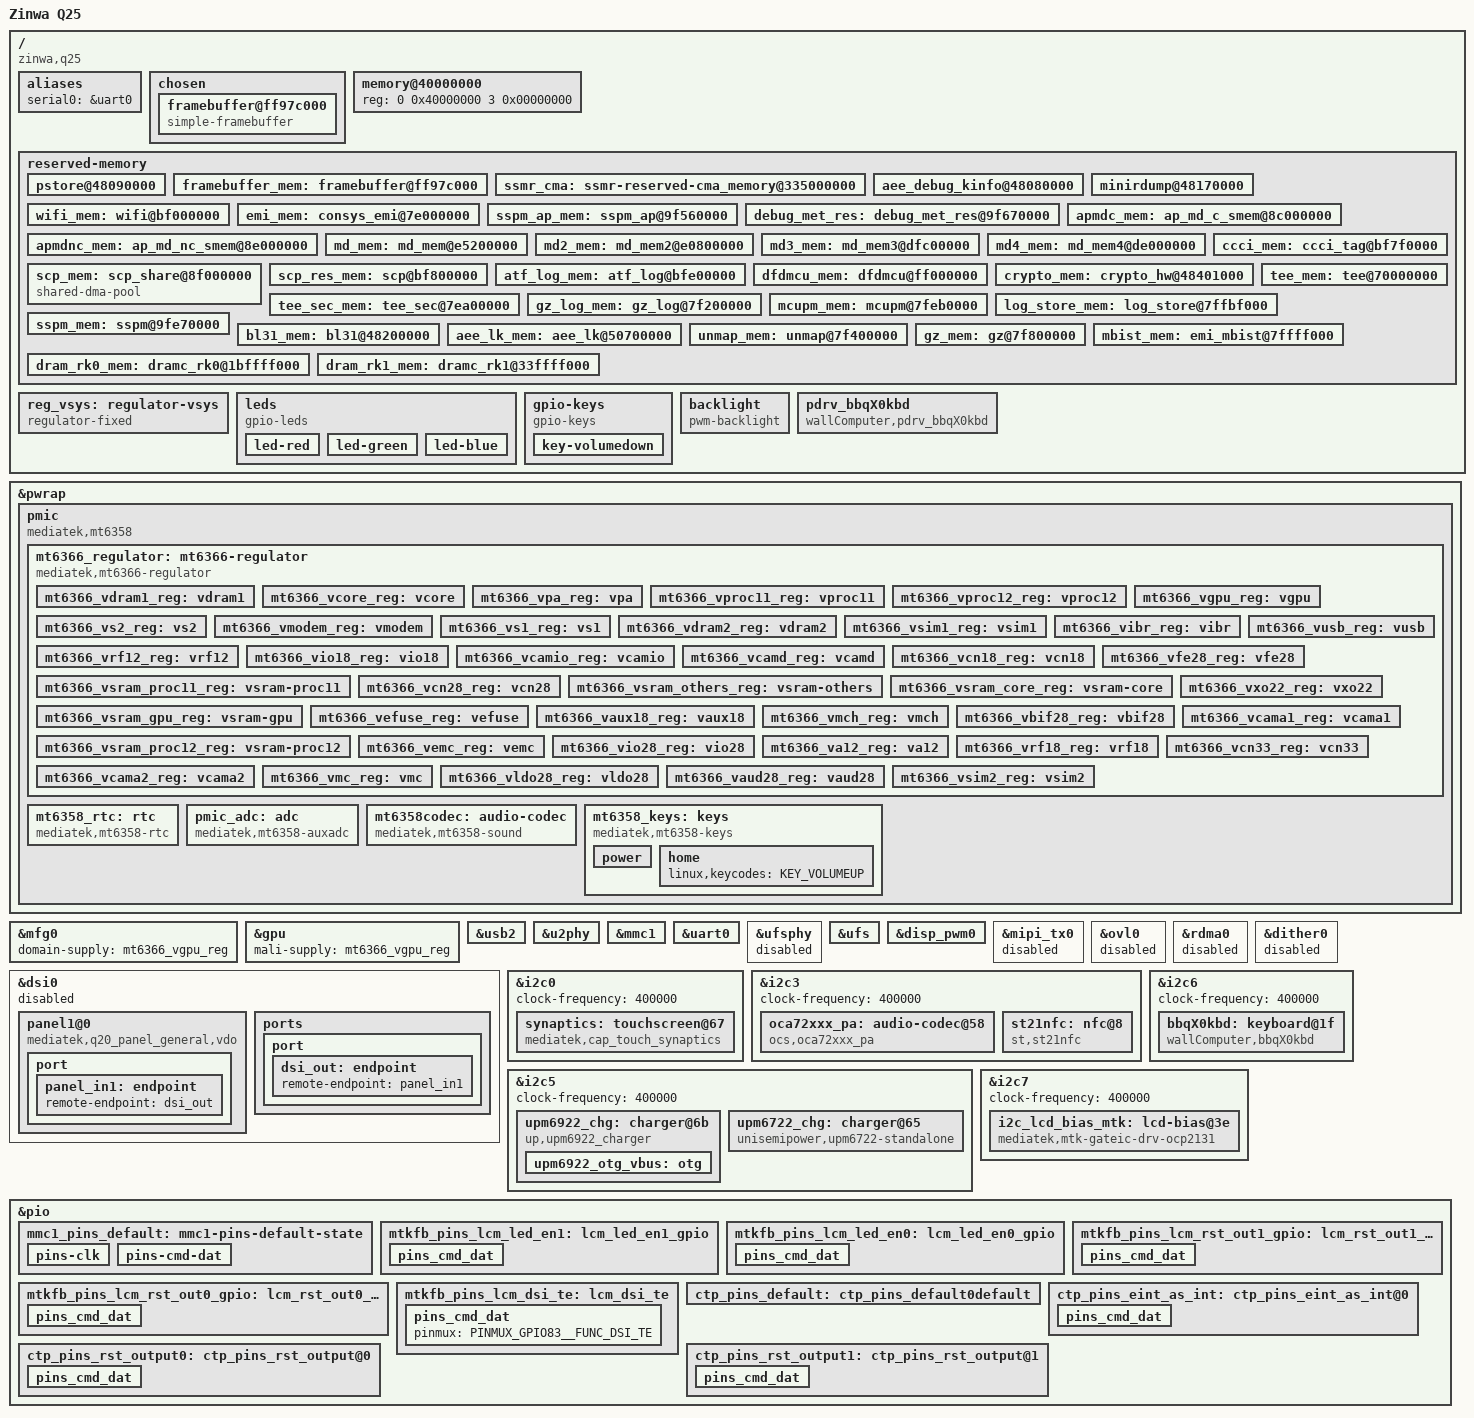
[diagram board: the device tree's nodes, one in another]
// SPDX-License-Identifier: GPL-2.0
/*
 * Device Tree Source for Zinwa Q25 (Xelex Q20 v12 / MediaTek Helio G99 MT6789 / MT8781)
 *
 * Mainline Linux 7.0+ DeviceTree with full Q25 peripheral wiring:
 * - BBQX0 Physical QWERTY Keyboard + Optical Trackpad (&i2c6 @ 0x1f + pdrv_bbqX0kbd)
 * - Synaptics S2716B 720x720 Capacitive Touchscreen (&i2c0 @ 0x67)
 * - Q20 720x720 60Hz MIPI DSI Video Panel (&dsi0) + OCP2131 Bias IC (&i2c7 @ 0x3e)
 * - UPM6922 Primary Charger + OTG VBUS (&i2c5 @ 0x6b) & UPM6722 Charge Pump (&i2c5 @ 0x65)
 * - OCA72xxx Smart Audio PA (&i2c3 @ 0x58)
 * - ST21NFC Controller (&i2c3 @ 0x08)
 * - RGB Status LEDs (GPIO 46/48/49) & Hardware Keys (PMIC Power/VolUp + GPIO 43 VolDown)
 * - Arm Mali-G57 MC2 GPU (Open-Source Panfrost)
 */

/dts-v1/;

#include <dt-bindings/input/input.h>
#include <dt-bindings/gpio/gpio.h>
#include <dt-bindings/iio/adc/mediatek,mt6358-auxadc.h>
#include <dt-bindings/regulator/mediatek,mt6397-regulator.h>
#include <dt-bindings/pinctrl/mediatek,mt6789-pinfunc.h>
#include "mt6789.dtsi"

/ {
	model = "Zinwa Q25";
	chassis-type = "handset";
	compatible = "zinwa,q25", "mediatek,mt8781", "mediatek,mt6789";

	#address-cells = <2>;
	#size-cells = <2>;

	aliases {
		serial0 = &uart0;
	};

	chosen: chosen {
		#address-cells = <2>;
		#size-cells = <2>;
		ranges;

		stdout-path = "serial0:921600n1";
		bootargs = "console=tty0 loglevel=8 earlycon panic=5 clk_ignore_unused pd_ignore_unused initcall_debug=1 ramoops.mem_address=0x48090000 ramoops.mem_size=0xcf000 ramoops.record_size=0x1000 ramoops.console_size=0x40000 ramoops.ftrace_size=0 ramoops.pmsg_size=0 arm64.nomte";
		linux,initrd-start = <0 0x66f00000>;
		linux,initrd-end = <0 0x69202911>;

		framebuffer@ff97c000 {
			compatible = "simple-framebuffer";
			memory-region = <&framebuffer_mem>;
			reg = <0 0xff97c000 0 ((720 + 16) * 720 * 4)>;
			width = <720>;
			height = <720>;
			stride = <((720 + 16) * 4)>;
			format = "a8r8g8b8";
		};
	};

	memory@40000000 {
		device_type = "memory";
		reg = <0 0x40000000 3 0x00000000>;
	};

	reserved-memory {
		#address-cells = <2>;
		#size-cells = <2>;
		ranges;

		pstore@48090000 {
			reg = <0 0x48090000 0 0xe0000>;
			no-map;
		};

		framebuffer_mem: framebuffer@ff97c000 {
			reg = <0 0xff97c000 0 0x683000>;
			no-map;
		};

		ssmr_cma: ssmr-reserved-cma_memory@335000000 {
			reg = <0x3 0x35000000 0 0x0a000000>;
			no-map;
		};

		aee_debug_kinfo@48080000 {
			reg = <0 0x48080000 0 0x10000>;
			no-map;
		};

		minirdump@48170000 {
			reg = <0 0x48170000 0 0x10000>;
			no-map;
		};

		wifi_mem: wifi@bf000000 {
			reg = <0 0xbf000000 0 0x600000>;
			no-map;
		};

		emi_mem: consys_emi@7e000000 {
			reg = <0 0x7e000000 0 0x500000>;
			no-map;
		};

		sspm_ap_mem: sspm_ap@9f560000 {
			reg = <0 0x9f560000 0 0x110000>;
			no-map;
		};

		debug_met_res: debug_met_res@9f670000 {
			reg = <0 0x9f670000 0 0x800000>;
			no-map;
		};

		apmdc_mem: ap_md_c_smem@8c000000 {
			reg = <0 0x8c000000 0 0x16a0000>;
			no-map;
		};

		apmdnc_mem: ap_md_nc_smem@8e000000 {
			reg = <0 0x8e000000 0 0xe10000>;
			no-map;
		};

		md_mem: md_mem@e5200000 {
			reg = <0 0xe5200000 0 0xe00000>;
			no-map;
		};

		md2_mem: md_mem2@e0800000 {
			reg = <0 0xe0800000 0 0x2c50000>;
			no-map;
		};

		md3_mem: md_mem3@dfc00000 {
			reg = <0 0xdfc00000 0 0x430000>;
			no-map;
		};

		md4_mem: md_mem4@de000000 {
			reg = <0 0xde000000 0 0x13f0000>;
			no-map;
		};

		ccci_mem: ccci_tag@bf7f0000 {
			reg = <0 0xbf7f0000 0 0x10000>;
			no-map;
		};

		scp_mem: scp_share@8f000000 {
			reg = <0 0x8f000000 0 0x7a0000>;
			compatible = "shared-dma-pool";
			no-map;
		};

		scp_res_mem: scp@bf800000 {
			reg = <0 0xbf800000 0 0x600000>;
			no-map;
		};

		atf_log_mem: atf_log@bfe00000 {
			reg = <0 0xbfe00000 0 0x200000>;
			no-map;
		};

		dfdmcu_mem: dfdmcu@ff000000 {
			reg = <0 0xff000000 0 0x100000>;
			no-map;
		};

		crypto_mem: crypto_hw@48401000 {
			reg = <0 0x48401000 0 0x1000>;
			no-map;
		};

		tee_mem: tee@70000000 {
			reg = <0 0x70000000 0 0x4600000>;
			no-map;
		};

		tee_sec_mem: tee_sec@7ea00000 {
			reg = <0 0x7ea00000 0 0x800000>;
			no-map;
		};

		gz_log_mem: gz_log@7f200000 {
			reg = <0 0x7f200000 0 0x41000>;
			no-map;
		};

		mcupm_mem: mcupm@7feb0000 {
			reg = <0 0x7feb0000 0 0x100000>;
			no-map;
		};

		log_store_mem: log_store@7ffbf000 {
			reg = <0 0x7ffbf000 0 0x40000>;
			no-map;
		};

		sspm_mem: sspm@9fe70000 {
			reg = <0 0x9fe70000 0 0x180000>;
			no-map;
		};

		bl31_mem: bl31@48200000 {
			reg = <0 0x48200000 0 0x200000>;
			no-map;
		};

		aee_lk_mem: aee_lk@50700000 {
			reg = <0 0x50700000 0 0x800000>;
			no-map;
		};

		unmap_mem: unmap@7f400000 {
			reg = <0 0x7f400000 0 0x400000>;
			no-map;
		};

		gz_mem: gz@7f800000 {
			reg = <0 0x7f800000 0 0x600000>;
			no-map;
		};

		mbist_mem: emi_mbist@7ffff000 {
			reg = <0 0x7ffff000 0 0x1000>;
			no-map;
		};

		dram_rk0_mem: dramc_rk0@1bffff000 {
			reg = <0x1 0xbffff000 0 0x1000>;
			no-map;
		};

		dram_rk1_mem: dramc_rk1@33ffff000 {
			reg = <0x3 0x3ffff000 0 0x1000>;
			no-map;
		};
	};

	reg_vsys: regulator-vsys {
		compatible = "regulator-fixed";
		regulator-name = "vsys";
		regulator-always-on;
		regulator-boot-on;
	};

	/* Zinwa Q25 RGB Notification LEDs */
	leds {
		compatible = "gpio-leds";

		led-red {
			label = "red";
			gpios = <&pio 46 GPIO_ACTIVE_HIGH>;
			default-state = "keep";
		};

		led-green {
			label = "green";
			gpios = <&pio 48 GPIO_ACTIVE_HIGH>;
			default-state = "keep";
		};

		led-blue {
			label = "blue";
			gpios = <&pio 49 GPIO_ACTIVE_HIGH>;
			default-state = "off";
		};
	};

	/* Volume Down GPIO key (KPD_KCOL0 on GPIO 43) */
	gpio-keys {
		compatible = "gpio-keys";

		key-volumedown {
			label = "Volume Down";
			gpios = <&pio 43 GPIO_ACTIVE_LOW>;
			linux,code = <KEY_VOLUMEDOWN>;
			debounce-interval = <15>;
			wakeup-source;
		};
	};

	/* Display PWM Backlight */
	backlight: backlight {
		compatible = "pwm-backlight";
		pwms = <&disp_pwm0 0 500000>;
		brightness-levels = <0 1023>;
		num-interpolated-steps = <1023>;
		default-brightness-level = <400>;
	};

	/* Zinwa Q25 Keyboard & Optical Trackpad Power Sequencing / Firmware Control */
	pdrv_bbqX0kbd: pdrv_bbqX0kbd {
		compatible = "wallComputer,pdrv_bbqX0kbd";
		irq-gpio = <&pio 12 GPIO_ACTIVE_HIGH>;
		int-gpios = <&pio 12 GPIO_ACTIVE_HIGH>;
		power-vdd-gpios = <&pio 159 GPIO_ACTIVE_HIGH>;
		power-1v8-gpios = <&pio 157 GPIO_ACTIVE_HIGH>;
		power-2v8-gpios = <&pio 158 GPIO_ACTIVE_HIGH>;
		firmware-download-gpios = <&pio 47 GPIO_ACTIVE_HIGH>;
	};
};

&pwrap {
	status = "okay";

	pmic: pmic {
		compatible = "mediatek,mt6358";
		interrupt-controller;
		interrupts-extended = <&pio 137 IRQ_TYPE_LEVEL_HIGH>;
		#interrupt-cells = <2>;

		mt6366_regulator: mt6366-regulator {
			compatible = "mediatek,mt6366-regulator", "mediatek,mt6358-regulator";

			vsys-ldo1-supply = <&reg_vsys>;
			vsys-ldo2-supply = <&reg_vsys>;
			vsys-ldo3-supply = <&reg_vsys>;
			vsys-vs1-supply = <&reg_vsys>;
			vsys-vs2-supply = <&reg_vsys>;
			vsys-vdram1-supply = <&reg_vsys>;
			vsys-vcore-supply = <&reg_vsys>;
			vsys-vpa-supply = <&reg_vsys>;
			vsys-vproc11-supply = <&reg_vsys>;
			vsys-vproc12-supply = <&reg_vsys>;
			vsys-vgpu-supply = <&reg_vsys>;
			vsys-vmodem-supply = <&reg_vsys>;
			vs1-ldo1-supply = <&mt6366_vs1_reg>;
			vs2-ldo1-supply = <&mt6366_vdram1_reg>;
			vs2-ldo2-supply = <&mt6366_vs2_reg>;
			vs2-ldo3-supply = <&mt6366_vs2_reg>;

			mt6366_vdram1_reg: vdram1 {
				regulator-name = "vdram1";
				regulator-min-microvolt = <500000>;
				regulator-max-microvolt = <2087500>;
				regulator-ramp-delay = <12500>;
				regulator-enable-ramp-delay = <0>;
				regulator-always-on;
				regulator-allowed-modes = <MT6397_BUCK_MODE_AUTO
				                           MT6397_BUCK_MODE_FORCE_PWM>;
			};

			mt6366_vcore_reg: vcore {
				regulator-name = "vcore";
				regulator-min-microvolt = <500000>;
				regulator-max-microvolt = <1293750>;
				regulator-ramp-delay = <6250>;
				regulator-enable-ramp-delay = <200>;
				regulator-always-on;
				regulator-allowed-modes = <MT6397_BUCK_MODE_AUTO
				                           MT6397_BUCK_MODE_FORCE_PWM>;
			};

			mt6366_vpa_reg: vpa {
				regulator-name = "vpa";
				regulator-min-microvolt = <500000>;
				regulator-max-microvolt = <3650000>;
				regulator-ramp-delay = <50000>;
				regulator-enable-ramp-delay = <250>;
				regulator-allowed-modes = <MT6397_BUCK_MODE_AUTO
				                           MT6397_BUCK_MODE_FORCE_PWM>;
			};

			mt6366_vproc11_reg: vproc11 {
				regulator-name = "vproc11";
				regulator-min-microvolt = <500000>;
				regulator-max-microvolt = <1293750>;
				regulator-ramp-delay = <6250>;
				regulator-enable-ramp-delay = <200>;
				regulator-always-on;
				regulator-allowed-modes = <MT6397_BUCK_MODE_AUTO
				                           MT6397_BUCK_MODE_FORCE_PWM>;
			};

			mt6366_vproc12_reg: vproc12 {
				regulator-name = "vproc12";
				regulator-min-microvolt = <500000>;
				regulator-max-microvolt = <1293750>;
				regulator-ramp-delay = <6250>;
				regulator-enable-ramp-delay = <200>;
				regulator-always-on;
				regulator-allowed-modes = <MT6397_BUCK_MODE_AUTO
				                           MT6397_BUCK_MODE_FORCE_PWM>;
			};

			mt6366_vgpu_reg: vgpu {
				regulator-name = "vgpu";
				regulator-min-microvolt = <675000>;
				regulator-max-microvolt = <1293750>;
				regulator-ramp-delay = <6250>;
				regulator-enable-ramp-delay = <200>;
				regulator-always-on;
				regulator-boot-on;
				regulator-allowed-modes = <MT6397_BUCK_MODE_AUTO
				                           MT6397_BUCK_MODE_FORCE_PWM>;

				regulator-coupled-with = <&mt6366_vsram_gpu_reg>;
				regulator-coupled-max-spread = <100000>;
			};

			mt6366_vs2_reg: vs2 {
				regulator-name = "vs2";
				regulator-min-microvolt = <500000>;
				regulator-max-microvolt = <2087500>;
				regulator-ramp-delay = <12500>;
				regulator-enable-ramp-delay = <0>;
				regulator-always-on;
			};

			mt6366_vmodem_reg: vmodem {
				regulator-name = "vmodem";
				regulator-min-microvolt = <500000>;
				regulator-max-microvolt = <1293750>;
				regulator-ramp-delay = <6250>;
				regulator-enable-ramp-delay = <900>;
				regulator-always-on;
				regulator-allowed-modes = <MT6397_BUCK_MODE_AUTO
				                           MT6397_BUCK_MODE_FORCE_PWM>;
			};

			mt6366_vs1_reg: vs1 {
				regulator-name = "vs1";
				regulator-min-microvolt = <1000000>;
				regulator-max-microvolt = <2587500>;
				regulator-ramp-delay = <12500>;
				regulator-enable-ramp-delay = <0>;
				regulator-always-on;
			};

			/* LPDDR4X, always on */
			mt6366_vdram2_reg: vdram2 {
				regulator-name = "vdram2";
				regulator-min-microvolt = <600000>;
				regulator-max-microvolt = <1800000>;
				regulator-enable-ramp-delay = <3300>;
				regulator-always-on;
			};

			mt6366_vsim1_reg: vsim1 {
				regulator-name = "vsim1";
				regulator-min-microvolt = <1700000>;
				regulator-max-microvolt = <3100000>;
				regulator-enable-ramp-delay = <540>;
			};

			mt6366_vibr_reg: vibr {
				regulator-name = "vibr";
				regulator-min-microvolt = <1200000>;
				regulator-max-microvolt = <3300000>;
				regulator-enable-ramp-delay = <60>;
			};

			mt6366_vrf12_reg: vrf12 {
				regulator-name = "vrf12";
				regulator-min-microvolt = <1200000>;
				regulator-max-microvolt = <1200000>;
				regulator-enable-ramp-delay = <120>;
				regulator-always-on;
				regulator-boot-on;
			};

			mt6366_vio18_reg: vio18 {
				regulator-name = "vio18";
				regulator-min-microvolt = <1800000>;
				regulator-max-microvolt = <1800000>;
				regulator-enable-ramp-delay = <2700>;
				regulator-always-on;
				regulator-boot-on;
			};

			mt6366_vusb_reg: vusb {
				regulator-name = "vusb";
				regulator-min-microvolt = <3000000>;
				regulator-max-microvolt = <3100000>;
				regulator-enable-ramp-delay = <270>;
				regulator-always-on;
			};

			mt6366_vcamio_reg: vcamio {
				regulator-name = "vcamio";
				regulator-min-microvolt = <1800000>;
				regulator-max-microvolt = <1800000>;
				regulator-enable-ramp-delay = <325>;
			};

			mt6366_vcamd_reg: vcamd {
				regulator-name = "vcamd";
				regulator-min-microvolt = <900000>;
				regulator-max-microvolt = <1800000>;
				regulator-enable-ramp-delay = <325>;
			};

			mt6366_vcn18_reg: vcn18 {
				regulator-name = "vcn18";
				regulator-min-microvolt = <1800000>;
				regulator-max-microvolt = <1800000>;
				regulator-enable-ramp-delay = <270>;
				regulator-boot-on;
				regulator-always-on;
			};

			mt6366_vfe28_reg: vfe28 {
				regulator-name = "vfe28";
				regulator-min-microvolt = <2800000>;
				regulator-max-microvolt = <2800000>;
				regulator-enable-ramp-delay = <270>;
				regulator-boot-on;
				regulator-always-on;
			};

			mt6366_vsram_proc11_reg: vsram-proc11 {
				regulator-name = "vsram_proc11";
				regulator-min-microvolt = <500000>;
				regulator-max-microvolt = <1293750>;
				regulator-ramp-delay = <6250>;
				regulator-enable-ramp-delay = <240>;
				regulator-always-on;
			};

			mt6366_vcn28_reg: vcn28 {
				regulator-name = "vcn28";
				regulator-min-microvolt = <2800000>;
				regulator-max-microvolt = <2800000>;
				regulator-enable-ramp-delay = <270>;
				regulator-boot-on;
				regulator-always-on;
			};

			mt6366_vsram_others_reg: vsram-others {
				regulator-name = "vsram_others";
				regulator-min-microvolt = <500000>;
				regulator-max-microvolt = <1293750>;
				regulator-ramp-delay = <6250>;
				regulator-enable-ramp-delay = <240>;
				regulator-always-on;
			};

			mt6366_vsram_core_reg: vsram-core {
				regulator-name = "vsram_core";
				regulator-min-microvolt = <500000>;
				regulator-max-microvolt = <1293750>;
				regulator-enable-ramp-delay = <240>;
				regulator-always-on;
			};

			mt6366_vsram_gpu_reg: vsram-gpu {
				regulator-name = "vsram_gpu";
				regulator-min-microvolt = <775000>;
				regulator-max-microvolt = <1293750>;
				regulator-ramp-delay = <6250>;
				regulator-enable-ramp-delay = <240>;
				regulator-always-on;
				regulator-boot-on;

				regulator-coupled-with = <&mt6366_vgpu_reg>;
				regulator-coupled-max-spread = <100000>;
			};

			mt6366_vxo22_reg: vxo22 {
				regulator-name = "vxo22";
				regulator-min-microvolt = <2200000>;
				regulator-max-microvolt = <2200000>;
				regulator-enable-ramp-delay = <120>;
				regulator-always-on;
				regulator-boot-on;
			};

			mt6366_vefuse_reg: vefuse {
				regulator-name = "vefuse";
				regulator-min-microvolt = <1700000>;
				regulator-max-microvolt = <1900000>;
				regulator-enable-ramp-delay = <270>;
			};

			mt6366_vaux18_reg: vaux18 {
				regulator-name = "vaux18";
				regulator-min-microvolt = <1800000>;
				regulator-max-microvolt = <1800000>;
				regulator-enable-ramp-delay = <270>;
				regulator-always-on;
				regulator-boot-on;
			};

			mt6366_vmch_reg: vmch {
				regulator-name = "vmch";
				regulator-min-microvolt = <2900000>;
				regulator-max-microvolt = <3300000>;
				regulator-enable-ramp-delay = <60>;
				regulator-always-on;
			};

			mt6366_vbif28_reg: vbif28 {
				regulator-name = "vbif28";
				regulator-min-microvolt = <2800000>;
				regulator-max-microvolt = <2800000>;
				regulator-enable-ramp-delay = <270>;
			};

			mt6366_vsram_proc12_reg: vsram-proc12 {
				regulator-name = "vsram_proc12";
				regulator-min-microvolt = <500000>;
				regulator-max-microvolt = <1293750>;
				regulator-ramp-delay = <6250>;
				regulator-enable-ramp-delay = <240>;
				regulator-always-on;
			};

			mt6366_vcama1_reg: vcama1 {
				regulator-name = "vcama1";
				regulator-min-microvolt = <1800000>;
				regulator-max-microvolt = <3000000>;
				regulator-enable-ramp-delay = <325>;
				regulator-boot-on;
				regulator-always-on;
			};

			mt6366_vemc_reg: vemc {
				regulator-name = "vemc";
				regulator-min-microvolt = <2900000>;
				regulator-max-microvolt = <3300000>;
				regulator-enable-ramp-delay = <60>;
				regulator-boot-on;
			};

			mt6366_vio28_reg: vio28 {
				regulator-name = "vio28";
				regulator-min-microvolt = <2800000>;
				regulator-max-microvolt = <2800000>;
				regulator-enable-ramp-delay = <270>;
				regulator-boot-on;
				regulator-always-on;
			};

			mt6366_va12_reg: va12 {
				regulator-name = "va12";
				regulator-min-microvolt = <1200000>;
				regulator-max-microvolt = <1200000>;
				regulator-enable-ramp-delay = <270>;
				regulator-always-on;
			};

			mt6366_vrf18_reg: vrf18 {
				regulator-name = "vrf18";
				regulator-min-microvolt = <1800000>;
				regulator-max-microvolt = <1800000>;
				regulator-enable-ramp-delay = <120>;
			};

			mt6366_vcn33_reg: vcn33 {
				regulator-name = "vcn33";
				regulator-min-microvolt = <3300000>;
				regulator-max-microvolt = <3500000>;
				regulator-enable-ramp-delay = <270>;
			};

			mt6366_vcama2_reg: vcama2 {
				regulator-name = "vcama2";
				regulator-min-microvolt = <1800000>;
				regulator-max-microvolt = <3000000>;
				regulator-enable-ramp-delay = <325>;
				regulator-boot-on;
				regulator-always-on;
			};

			mt6366_vmc_reg: vmc {
				regulator-name = "vmc";
				regulator-min-microvolt = <2900000>;
				regulator-max-microvolt = <3300000>;
				regulator-enable-ramp-delay = <60>;
				regulator-boot-on;
				regulator-always-on;
			};

			mt6366_vldo28_reg: vldo28 {
				regulator-name = "vldo28";
				regulator-min-microvolt = <2800000>;
				regulator-max-microvolt = <2800000>;
				regulator-enable-ramp-delay = <270>;
				regulator-boot-on;
				regulator-always-on;
			};

			mt6366_vaud28_reg: vaud28 {
				regulator-name = "vaud28";
				regulator-min-microvolt = <2800000>;
				regulator-max-microvolt = <2800000>;
				regulator-enable-ramp-delay = <270>;
				regulator-boot-on;
				regulator-always-on;
			};

			mt6366_vsim2_reg: vsim2 {
				regulator-name = "vsim2";
				regulator-min-microvolt = <1700000>;
				regulator-max-microvolt = <3100000>;
				regulator-enable-ramp-delay = <540>;
			};
		};

		mt6358_rtc: rtc {
			compatible = "mediatek,mt6358-rtc";
		};

		pmic_adc: adc {
			compatible = "mediatek,mt6358-auxadc";
			#io-channel-cells = <1>;
		};

		mt6358codec: audio-codec {
			compatible = "mediatek,mt6358-sound";
			Avdd-supply = <&mt6366_vaud28_reg>;
			mediatek,dmic-mode = <0>;
		};

		mt6358_keys: keys {
			compatible = "mediatek,mt6358-keys";

			power-off-time-sec = <10>;
			mediatek,long-press-mode = <1>;

			power {
				linux,keycodes = <KEY_POWER>;
				wakeup-source;
			};

			home {
				linux,keycodes = <KEY_VOLUMEUP>;
			};
		};
	};
};

&mfg0 {
	domain-supply = <&mt6366_vgpu_reg>;
};

/* Open-Source Panfrost GPU (Arm Mali-G57 MC2) */
&gpu {
	/delete-property/ operating-points-v2;
	mali-supply = <&mt6366_vgpu_reg>;
	status = "okay";
};

&usb2 {
	status = "okay";
	dr_mode = "peripheral";
	maximum-speed = "high-speed";
};

&u2phy {
	status = "okay";
};

&mmc1 {
	status = "okay";

	pinctrl-names = "default", "state_uhs";
	pinctrl-0 = <&mmc1_pins_default>;
	pinctrl-1 = <&mmc1_pins_default>;

	bus-width = <4>;
	max-frequency = <200000000>;

	cap-sd-highspeed;
	sd-uhs-sdr12;
	sd-uhs-sdr25;
	sd-uhs-sdr50;
	sd-uhs-sdr104;
	sd-uhs-ddr50;

	cd-debounce-delay-ms = <0>;
	cd-gpios = <&pio 7 GPIO_ACTIVE_HIGH>;

	vmmc-supply = <&mt6366_vmch_reg>;
	vqmmc-supply = <&mt6366_vmc_reg>;
};

&uart0 {
	status = "okay";
};

&ufsphy {
	status = "disabled";
};

&ufs {
	status = "okay";
	/delete-property/ phys;
	vcc-supply = <&mt6366_vemc_reg>;
	clocks = <&infracfg_ao CLK_IFRAO_UFS>,
	         <&infracfg_ao CLK_IFRAO_UFS_SAP_BCLK>,
	         <&infracfg_ao CLK_IFRAO_UNIPRO_TICK>,
	         <&infracfg_ao CLK_IFRAO_UNIPRO_SYSCLK>,
	         <&infracfg_ao CLK_IFRAO_UFS_AES>,
	         <&topckgen CLK_TOP_AES_UFSFDE>,
	         <&topckgen CLK_TOP_UFS>,
	         <&topckgen CLK_TOP_UFS_SEL>;
	clock-names = "ufs", "ufs_mp", "unipro_tick", "unipro_sys",
	              "ufs_aes", "ufsfde_ck", "ufs_ck", "ufs_sel";
	freq-table-hz = <0 0>, <0 0>, <0 0>, <0 0>,
	                <0 0>, <0 0>, <0 0>, <0 0>;
};

&disp_pwm0 {
	status = "okay";
};

/* Keep mtk-drm display pipeline disabled while using simple-framebuffer */
&mipi_tx0 {
	status = "disabled";
};

&ovl0 {
	status = "disabled";
};

&rdma0 {
	status = "disabled";
};

&dither0 {
	status = "disabled";
};

/* Q20 720x720 60Hz MIPI DSI Video Panel */
&dsi0 {
	status = "disabled";
	#address-cells = <1>;
	#size-cells = <0>;

	panel1@0 {
		compatible = "mediatek,q20_panel_general,vdo";
		reg = <0>;
		reset-gpios = <&pio 85 GPIO_ACTIVE_HIGH>;
		avdd-gpios = <&pio 156 GPIO_ACTIVE_HIGH>;
		backlight = <&backlight>;
		board_name = "q20_v12";

		port {
			panel_in1: endpoint {
				remote-endpoint = <&dsi_out>;
			};
		};
	};

	ports {
		port {
			dsi_out: endpoint {
				remote-endpoint = <&panel_in1>;
			};
		};
	};
};

/* I2C0: Synaptics S2716B 720x720 Capacitive Touchscreen */
&i2c0 {
	clock-frequency = <400000>;
	status = "okay";

	synaptics: touchscreen@67 {
		compatible = "mediatek,cap_touch_synaptics", "synaptics,dsx-i2c";
		reg = <0x67>;
		boot_mode = <&chosen>;
		synaptics,irq-gpio = <&pio 9 GPIO_ACTIVE_HIGH>;
		synaptics,irq-on-state = <0>;
		synaptics,reset-gpio = <&pio 152 GPIO_ACTIVE_HIGH>;
		synaptics,reset-on-state = <0>;
		synaptics,reset-active-ms = <20>;
		synaptics,reset-delay-ms = <200>;
		synaptics,power-gpio = <&pio 27 GPIO_ACTIVE_HIGH>;
		synaptics,power-on-state = <1>;
		synaptics,power-delay-ms = <200>;
		synaptics,input-device-name = "s2716b_ts";
	};
};

/* I2C3: OCA72xxx Smart Audio PA + ST21NFC Controller */
&i2c3 {
	clock-frequency = <400000>;
	status = "okay";

	oca72xxx_pa: audio-codec@58 {
		compatible = "ocs,oca72xxx_pa", "mediatek,k9_pa";
		reg = <0x58>;
		dev_index = <0>;
		status = "okay";
	};

	st21nfc: nfc@8 {
		compatible = "st,st21nfc";
		reg = <0x08>;
		interrupt-parent = <&pio>;
		interrupts = <1 IRQ_TYPE_LEVEL_LOW>;
		reset-gpios = <&pio 150 GPIO_ACTIVE_HIGH>;
		irq-gpios = <&pio 1 GPIO_ACTIVE_HIGH>;
		clkreq-gpios = <&pio 68 GPIO_ACTIVE_HIGH>;
		status = "okay";
	};
};

/* I2C5: UPM6922 Primary Charger + OTG VBUS & UPM6722 Standalone Charge Pump */
&i2c5 {
	clock-frequency = <400000>;
	status = "okay";

	upm6922_chg: charger@6b {
		compatible = "up,upm6922_charger";
		reg = <0x6b>;
		status = "okay";
		up,intr_gpio = <&pio 37 GPIO_ACTIVE_HIGH>;

		up,upm6922,ichg = <3000>;
		up,upm6922,iprechg = <180>;
		up,upm6922,iterm = <200>;
		up,upm6922,vreg = <4440>;
		up,upm6922,vindpm = <4600>;
		up,upm6922,boostv = <5000>;
		up,upm6922,boosti = <1200>;
		up,upm6922,vac-ovp = <14000>;

		boot_mode = <&chosen>;
		phys = <&u2port0 PHY_TYPE_USB2>;
		phy-names = "usb2-phy";
		io-channels = <&pmic_adc MT6358_AUXADC_VCDT>,
		              <&pmic_adc MT6358_AUXADC_BATADC>;
		io-channel-names = "vbus", "vbat";

		upm6922_otg_vbus: otg {
			regulator-compatible = "upm6922,otg-vbus";
			regulator-name = "usb-otg-vbus";
		};
	};

	upm6722_chg: charger@65 {
		compatible = "unisemipower,upm6722-standalone";
		reg = <0x65>;
		status = "okay";
		upm6722,irq-gpio = <&pio 10 GPIO_ACTIVE_HIGH>;

		upm6722,bat-ocp-disable;
		upm6722,tsbus-flt-disable;
		upm6722,tsbat-flt-disable;
		upm6722,wdt-disable;
		upm6722,vbus-errhi-disable;
		upm6722,bat-ocp-alm-disable;

		upm6722,bat-ovp-threshold = <4525>;
		upm6722,bat-ocp-threshold = <8200>;
		upm6722,bus-ovp-threshold = <12000>;
		upm6722,bus-ocp-threshold = <5100>;
		upm6722,bus-ucp-threshold = <250>;
		upm6722,bus-rcp-threshold = <300>;
		upm6722,vac1-ovp-threshold = <18000>;
		upm6722,vac2-ovp-threshold = <18000>;
		upm6722,vout-ovp-threshold = <5000>;
		upm6722,tdie-flt-threshold = <140>;
		upm6722,tsbus-flt-threshold = <4102>;
		upm6722,tsbat-flt-threshold = <4102>;

		upm6722,bat-ovp-alm-threshold = <4510>;
		upm6722,bat-ocp-alm-threshold = <8000>;
		upm6722,bat-ucp-alm-threshold = <0>;
		upm6722,bus-ovp-alm-threshold = <11800>;
		upm6722,bus-ocp-alm-threshold = <5000>;
		upm6722,tdie-alm-threshold = <125>;

		upm6722,sense-resistor-mohm = <5>;
		upm6722,ss-timeout = <10000>;
		upm6722,wdt-set = <30000>;
		upm6722,chg-config-1 = <1>;
		upm6722,fsw-set = <5>;
		upm6722,freq-shift = <0>;
		upm6722,ibus-ucp-fall-dg-sel = <0>;

		upm6722,adc-enable;
		upm6722,adc-rate = <0>;
		upm6722,adc-avg = <0>;
		upm6722,adc-avg-init = <0>;
		upm6722,adc-sample-bit = <0>;
	};
};

/* I2C6: BBQX0 Physical QWERTY Keyboard & Optical Trackpad */
&i2c6 {
	clock-frequency = <400000>;
	status = "okay";

	bbqX0kbd: keyboard@1f {
		compatible = "wallComputer,bbqX0kbd";
		reg = <0x1f>;
		interrupt-parent = <&pio>;
		interrupts = <12 IRQ_TYPE_EDGE_FALLING>;
	};
};

/* I2C7: OCP2131 LCD +/-5.8V Bias IC */
&i2c7 {
	clock-frequency = <400000>;
	status = "okay";

	i2c_lcd_bias_mtk: lcd-bias@3e {
		compatible = "mediatek,mtk-gateic-drv-ocp2131";
		reg = <0x3e>;
		id = <6>;
		gate-power-gpios = <&pio 84 GPIO_ACTIVE_HIGH>;
		status = "okay";
	};
};

&pio {
	mmc1_pins_default: mmc1-pins-default-state {
		pins-clk {
			pinmux = <PINMUX_GPIO71__FUNC_MSDC1_CLK>;
			drive-strength = <3>;
			bias-pull-down = <MTK_PUPD_SET_R1R0_10>;
		};

		pins-cmd-dat {
			pinmux = <PINMUX_GPIO73__FUNC_MSDC1_DAT0>,
			         <PINMUX_GPIO74__FUNC_MSDC1_DAT1>,
			         <PINMUX_GPIO75__FUNC_MSDC1_DAT2>,
			         <PINMUX_GPIO76__FUNC_MSDC1_DAT3>,
			         <PINMUX_GPIO72__FUNC_MSDC1_CMD>;
			input-enable;
			drive-strength = <3>;
			bias-pull-up = <MTK_PUPD_SET_R1R0_01>;
		};
	};

	mtkfb_pins_lcm_led_en1: lcm_led_en1_gpio {
		pins_cmd_dat {
			pinmux = <PINMUX_GPIO84__FUNC_GPIO84>;
			slew-rate = <1>;
			output-high;
		};
	};

	mtkfb_pins_lcm_led_en0: lcm_led_en0_gpio {
		pins_cmd_dat {
			pinmux = <PINMUX_GPIO84__FUNC_GPIO84>;
			slew-rate = <1>;
			output-low;
		};
	};

	mtkfb_pins_lcm_rst_out1_gpio: lcm_rst_out1_gpio {
		pins_cmd_dat {
			pinmux = <PINMUX_GPIO85__FUNC_GPIO85>;
			slew-rate = <1>;
			output-high;
		};
	};

	mtkfb_pins_lcm_rst_out0_gpio: lcm_rst_out0_gpio {
		pins_cmd_dat {
			pinmux = <PINMUX_GPIO85__FUNC_GPIO85>;
			slew-rate = <1>;
			output-low;
		};
	};

	mtkfb_pins_lcm_dsi_te: lcm_dsi_te {
		pins_cmd_dat {
			pinmux = <PINMUX_GPIO83__FUNC_DSI_TE>;
		};
	};

	ctp_pins_default: ctp_pins_default0default {
	};

	ctp_pins_eint_as_int: ctp_pins_eint_as_int@0 {
		pins_cmd_dat {
			pinmux = <PINMUX_GPIO9__FUNC_GPIO9>;
			slew-rate = <0>;
		};
	};

	ctp_pins_rst_output0: ctp_pins_rst_output@0 {
		pins_cmd_dat {
			pinmux = <PINMUX_GPIO152__FUNC_GPIO152>;
			slew-rate = <1>;
			output-low;
		};
	};

	ctp_pins_rst_output1: ctp_pins_rst_output@1 {
		pins_cmd_dat {
			pinmux = <PINMUX_GPIO152__FUNC_GPIO152>;
			slew-rate = <1>;
			output-high;
		};
	};
};
